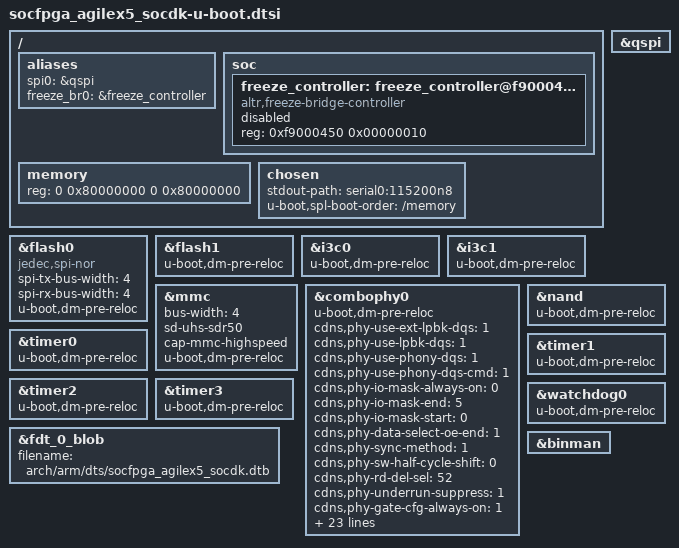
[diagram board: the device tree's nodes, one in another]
// SPDX-License-Identifier: GPL-2.0+
/*
 * U-Boot additions
 *
 * Copyright (C) 2022-2023 Intel Corporation <www.intel.com> 
 */

#include "socfpga_agilex5-u-boot.dtsi"

/{
	aliases {
		spi0 = &qspi;
		freeze_br0 = &freeze_controller;
	};

	soc {
		freeze_controller: freeze_controller@f9000450 {
			compatible = "altr,freeze-bridge-controller";
			reg = <0xf9000450 0x00000010>;
			status = "disabled";
		};
	};

	memory {
		/* 2GB on Simics*/
		reg = <0 0x80000000 0 0x80000000>;
	};

	chosen {
		stdout-path = "serial0:115200n8";
		u-boot,spl-boot-order = &mmc,&flash0,&nand,"/memory";
	};
};

&flash0 {
	compatible = "jedec,spi-nor";
	spi-tx-bus-width = <4>;
	spi-rx-bus-width = <4>;
	u-boot,dm-pre-reloc;
	/delete-property/ cdns,read-delay;
};

&flash1 {
	u-boot,dm-pre-reloc;
};

&i3c0 {
    u-boot,dm-pre-reloc;
};

&i3c1 {
    u-boot,dm-pre-reloc;
};

&mmc {
	status = "okay";
	bus-width = <4>;
	sd-uhs-sdr50;
	cap-mmc-highspeed;
	u-boot,dm-pre-reloc;
};

&combophy0 {
	status = "okay";
	u-boot,dm-pre-reloc;
	cdns,phy-use-ext-lpbk-dqs = <1>;
	cdns,phy-use-lpbk-dqs = <1>;
	cdns,phy-use-phony-dqs = <1>;
	cdns,phy-use-phony-dqs-cmd = <1>;
	cdns,phy-io-mask-always-on = <0>;
	cdns,phy-io-mask-end = <5>;
	cdns,phy-io-mask-start = <0>;
	cdns,phy-data-select-oe-end = <1>;
	cdns,phy-sync-method = <1>;
	cdns,phy-sw-half-cycle-shift = <0>;
	cdns,phy-rd-del-sel = <52>;
	cdns,phy-underrun-suppress = <1>;
	cdns,phy-gate-cfg-always-on = <1>;
	cdns,phy-param-dll-bypass-mode = <1>;
	cdns,phy-param-phase-detect-sel = <2>;
	cdns,phy-param-dll-start-point = <254>;
	cdns,phy-read-dqs-cmd-delay = <0>;
	cdns,phy-clk-wrdqs-delay = <0>;
	cdns,phy-clk-wr-delay = <0>;
	cdns,phy-read-dqs-delay = <0>;
	cdns,phy-phony-dqs-timing = <0>;
	cdns,hrs09-rddata-en = <1>;
	cdns,hrs09-rdcmd-en = <1>;
	cdns,hrs09-extended-wr-mode = <1>;
	cdns,hrs09-extended-rd-mode = <1>;
	cdns,hrs10-hcsdclkadj = <3>;
	cdns,hrs16-wrdata1-sdclk-dly = <0>;
	cdns,hrs16-wrdata0-sdclk-dly = <0>;
	cdns,hrs16-wrcmd1-sdclk-dly = <0>;
	cdns,hrs16-wrcmd0-sdclk-dly = <0>;
	cdns,hrs16-wrdata1-dly = <0>;
	cdns,hrs16-wrdata0-dly = <0>;
	cdns,hrs16-wrcmd1-dly = <0>;
	cdns,hrs16-wrcmd0-dly = <0>;
	cdns,hrs07-rw-compensate = <10>;
	cdns,hrs07-idelay-val = <0>;
};

&qspi {
	status = "okay";
};

&nand {
    u-boot,dm-pre-reloc;
};

&timer0 {
	u-boot,dm-pre-reloc;
};

&timer1 {
	u-boot,dm-pre-reloc;
};

&timer2 {
	u-boot,dm-pre-reloc;
};

&timer3 {
	u-boot,dm-pre-reloc;
};

&watchdog0 {
	u-boot,dm-pre-reloc;
};

#if !defined(CONFIG_SOCFPGA_SECURE_VAB_AUTH)
&fdt_0_blob {
	filename = "arch/arm/dts/socfpga_agilex5_socdk.dtb";
};

/* To add NAND dtb when ready in future */

&binman {
	/delete-node/ kernel;
};
#endif

